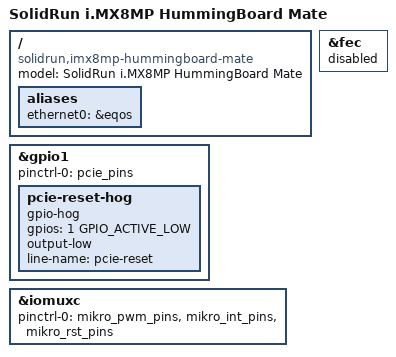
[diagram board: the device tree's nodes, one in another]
// SPDX-License-Identifier: (GPL-2.0+ OR MIT)
/*
 * Copyright 2025 Josua Mayer <josua@solid-run.com>
 */

/dts-v1/;

#define IMX8MP_SR_DTS_2025
#include "imx8mp-sr-som.dtsi"
#include "imx8mp-hummingboard-pulse-common.dtsi"
#include "imx8mp-hummingboard-pulse-hdmi.dtsi"

/ {
	model = "SolidRun i.MX8MP HummingBoard Mate";
	compatible = "solidrun,imx8mp-hummingboard-mate",
		     "solidrun,imx8mp-sr-som", "fsl,imx8mp";

	aliases {
		ethernet0 = &eqos;
		/delete-property/ ethernet1;
	};
};

&fec {
	/* this board does not use second phy / ethernet on SoM */
	status = "disabled";
};

&gpio1 {
	pinctrl-0 = <&pcie_pins>;
	pinctrl-names = "default";

	pcie-reset-hog {
		gpio-hog;
		gpios = <1 GPIO_ACTIVE_LOW>;
		output-low;
		line-name = "pcie-reset";
	};
};

&iomuxc {
	pinctrl-names = "default";
	pinctrl-0 = <&mikro_pwm_pins>, <&mikro_int_pins>, <&mikro_rst_pins>;
};
